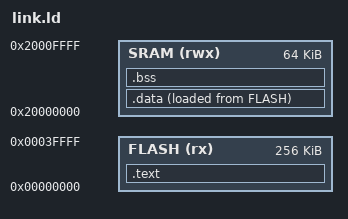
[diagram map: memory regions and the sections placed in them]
/* Stellaris LM3S6965, as QEMU's `lm3s6965evb` machine models it.
 *
 * 256K of flash at 0, 64K of SRAM at 0x20000000. The vector table must be the
 * first thing in flash — the core reads the initial stack pointer from word 0
 * and the reset vector from word 1 before executing anything.
 */
ENTRY(Reset_Handler)

MEMORY
{
  FLASH (rx)  : ORIGIN = 0x00000000, LENGTH = 256K
  SRAM  (rwx) : ORIGIN = 0x20000000, LENGTH = 64K
}

_estack = ORIGIN(SRAM) + LENGTH(SRAM);

SECTIONS
{
  .text :
  {
    KEEP(*(.isr_vector))
    *(.text*)
    *(.rodata*)
    . = ALIGN(4);
  } > FLASH

  _sidata = LOADADDR(.data);

  .data :
  {
    . = ALIGN(4);
    _sdata = .;
    *(.data*)
    . = ALIGN(4);
    _edata = .;
  } > SRAM AT > FLASH

  .bss :
  {
    . = ALIGN(4);
    _sbss = .;
    *(.bss*)
    *(COMMON)
    . = ALIGN(4);
    _ebss = .;
  } > SRAM

  /DISCARD/ : { *(.ARM.exidx*) *(.note*) *(.comment) }
}
